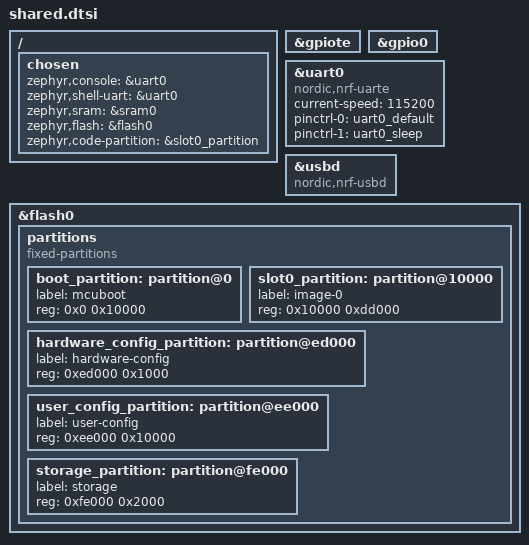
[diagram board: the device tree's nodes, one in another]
&gpiote {
    status = "okay";
};

&gpio0 {
    status = "okay";
};

&uart0 {
    compatible = "nordic,nrf-uarte";
    status = "okay";
    current-speed = <115200>;
    pinctrl-0 = <&uart0_default>;
    pinctrl-1 = <&uart0_sleep>;
    pinctrl-names = "default", "sleep";
};

zephyr_udc0: &usbd {
    compatible = "nordic,nrf-usbd";
    status = "okay";
};

/ {
    chosen {
        zephyr,console = &uart0;
        zephyr,shell-uart = &uart0;
        zephyr,sram = &sram0;
        zephyr,flash = &flash0;
        zephyr,code-partition = &slot0_partition;
    };
};

&flash0 {
    partitions {
        compatible = "fixed-partitions";
        #address-cells = <1>;
        #size-cells = <1>;

        boot_partition: partition@0 {
            label = "mcuboot";
            reg = <0x0 0x10000>;
        };
        slot0_partition: partition@10000 {
            label = "image-0";
            reg = <0x10000 0xdd000>;
        };
        hardware_config_partition: partition@ed000 {
            label = "hardware-config";
            reg = <0xed000 0x1000>;
        };
        user_config_partition: partition@ee000 {
            label = "user-config";
            reg = <0xee000 0x10000>;
        };
        storage_partition: partition@fe000 {
            label = "storage";
            reg = <0xfe000 0x2000>;
        };
    };
};
